# MDR1986VK01 register map
File version: 1.0.2
Registers are 32-bit, read-write, no defined reset value unless marked. A register's access mark holds for its fields unless they carry their own. Offsets are from the block's base; [hi:lo] are bit positions; {n}, {i} and the like mark numbered series; 'fields as' and 'values as' point back to an identical list.

## MDR_BKP — MDR_BKP description
Base 0x40001000
{0x0+4i} REG_{i:02} (i=0..59)
0xF0 KEY — KEY description
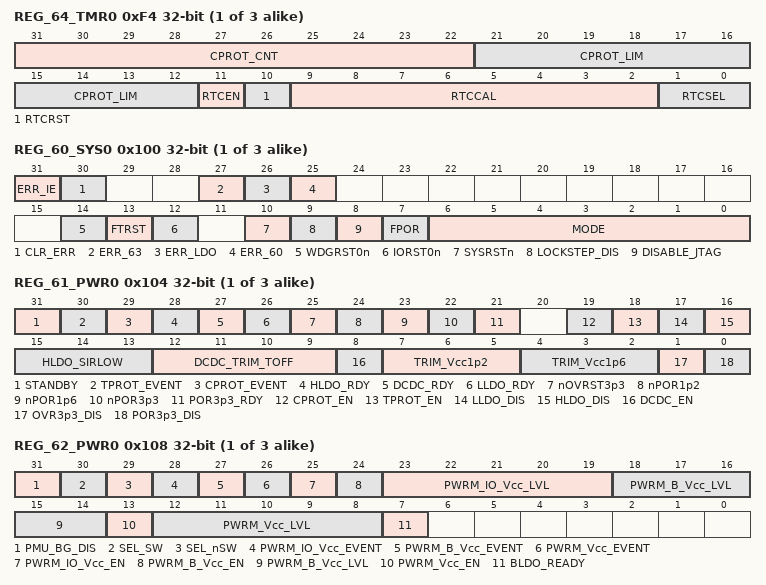
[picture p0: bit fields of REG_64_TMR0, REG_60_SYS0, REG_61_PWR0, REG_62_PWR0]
{0xF4+4i} REG_64_TMR{i} (i=0..2) — REG_64_TMR{i} description
  [31:22] CPROT_CNT ro — CPROT_CNT description
  [21:12] CPROT_LIM — CPROT_LIM description
  [11] RTCEN — RTCEN description
  [10] RTCRST — RTCRST description
  [9:2] RTCCAL — RTCCAL description
  [1:0] RTCSEL — RTCSEL description
    0=LSI (LSI selected); 1=LSE (LSE selected); 2=RTC_CLK (RTC_CLK selected)
{0x100+0x10*i} REG_60_SYS{i} (i=0..2) — REG_60_SYS{i} description
  [31] ERR_IE — ERR_IE description
  [30] CLR_ERR — CLR_ERR description
  [27] ERR_63 — ERR_63 description
  [26] ERR_LDO — ERR_LDO description
  [25] ERR_60 — ERR_60 description
  [14] WDGRST0n — WDGRST0n description
  [13] FTRST — FTRST description
  [12] IORST0n — IORST0n description
  [10] SYSRSTn — SYSRSTn description
  [9] LOCKSTEP_DIS — LOCKSTEP_DIS description
  [8] DISABLE_JTAG — DISABLE_JTAG description
  [7] FPOR — FPOR description
  [6:0] MODE — MODE description
{0x104+0x10*i} REG_61_PWR{i} (i=0..2) — REG_61_PWR{i} description
  [31] STANDBY — STANDBY description
  [30] TPROT_EVENT ro — TPROT_EVENT description
  [29] CPROT_EVENT ro — CPROT_EVENT description
  [28] HLDO_RDY ro — HLDO_RDY description
  [27] DCDC_RDY ro — DCDC_RDY description
  [26] LLDO_RDY ro — LLDO_RDY description
  [25] nOVRST3p3 ro — nOVRST3p3 description
  [24] nPOR1p2 ro — nPOR1p2 description
  [23] nPOR1p6 ro — nPOR1p6 description
  [22] nPOR3p3 ro — nPOR3p3 description
  [21] POR3p3_RDY ro — POR3p3_RDY description
  [19] CPROT_EN — CPROT_EN description
  [18] TPROT_EN — TPROT_EN description
  [17] LLDO_DIS — LLDO_DIS description
  [16] HLDO_DIS — HLDO_DIS description
  [15:13] HLDO_SIRLOW — HLDO_SIRLOW description
  [12:9] DCDC_TRIM_TOFF — DCDC_TRIM_TOFF description
  [8] DCDC_EN — DCDC_EN description
  [7:5] TRIM_Vcc1p2 — TRIM_Vcc1p2 description
  [4:2] TRIM_Vcc1p6 — TRIM_Vcc1p6 description
  [1] OVR3p3_DIS — OVR3p3_DIS description
  [0] POR3p3_DIS — POR3p3_DIS description
{0x108+0x10*i} REG_62_PWR{i} (i=0..2) — REG_62_PWR{i} description
  [31] PMU_BG_DIS — PMU_BG_DIS description
  [30] SEL_SW ro — SEL_SW description
  [29] SEL_nSW ro — SEL_nSW description
  [28] PWRM_IO_Vcc_EVENT ro — PWRM_IO_Vcc_EVENT description
  [27] PWRM_B_Vcc_EVENT ro — PWRM_B_Vcc_EVENT description
  [26] PWRM_Vcc_EVENT ro — PWRM_Vcc_EVENT description
  [25] PWRM_IO_Vcc_EN — PWRM_IO_Vcc_EN description
  [24] PWRM_B_Vcc_EN — PWRM_B_Vcc_EN description
  [23:19] PWRM_IO_Vcc_LVL — PWRM_IO_Vcc_LVL description
  [18:14] PWRM_B_Vcc_LVL — PWRM_B_Vcc_LVL description
  [13] PWRM_Vcc_EN — PWRM_Vcc_EN description
  [12:8] PWRM_Vcc_LVL — PWRM_Vcc_LVL description
  [7] BLDO_READY ro — BLDO_READY description
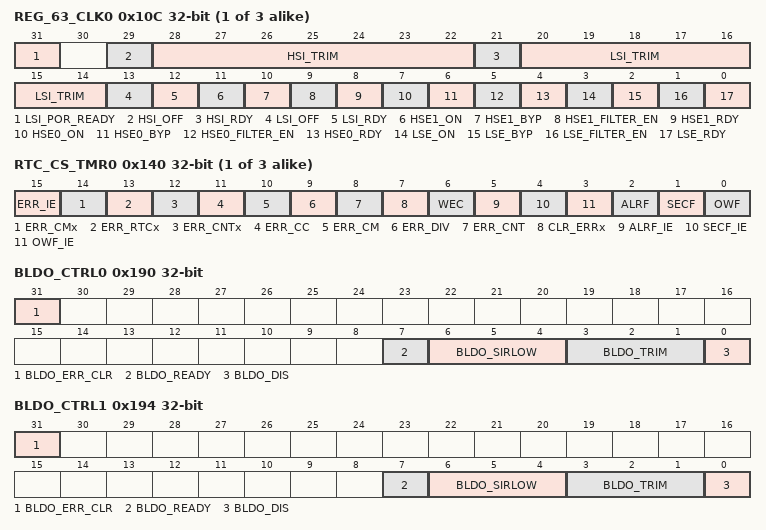
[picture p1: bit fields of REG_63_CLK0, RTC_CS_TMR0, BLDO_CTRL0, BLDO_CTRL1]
{0x10C+0x10*i} REG_63_CLK{i} (i=0..2) — REG_63_CLK{i} description
  [31] LSI_POR_READY ro — LSI_POR_READY description
  [29] HSI_OFF — HSI_OFF description
  [28:22] HSI_TRIM — HSI_TRIM description
  [21] HSI_RDY ro — HSI_RDY description
  [20:14] LSI_TRIM — LSI_TRIM description
  [13] LSI_OFF — LSI_OFF description
  [12] LSI_RDY ro — LSI_RDY description
  [11] HSE1_ON — HSE1_ON description
  [10] HSE1_BYP — HSE1_BYP description
  [9] HSE1_FILTER_EN — HSE1_FILTER_EN description
  [8] HSE1_RDY ro — HSE1_RDY description
  [7] HSE0_ON — HSE0_ON description
  [6] HSE0_BYP — HSE0_BYP description
  [5] HSE0_FILTER_EN — HSE0_FILTER_EN description
  [4] HSE0_RDY ro — HSE0_RDY description
  [3] LSE_ON — LSE_ON description
  [2] LSE_BYP — LSE_BYP description
  [1] LSE_FILTER_EN — LSE_FILTER_EN description
  [0] LSE_RDY ro — LSE_RDY description
{0x130+0x20*i} RTC_CNT_TMR{i} (i=0..2) — RTC_CNT_TMR{i} description
{0x134+0x20*i} RTC_DIV_TMR{i} (i=0..2) — RTC_DIV_TMR{i} description
  [19:0] DIV — DIV description
{0x138+0x20*i} RTC_PRL_TMR{i} (i=0..2) — RTC_PRL_TMR{i} description
  [19:0] PRL — PRL description
{0x13C+0x20*i} RTC_ALRM_TMR{i} (i=0..2) — RTC_ALRM_TMR{i} description
{0x140+0x20*i} RTC_CS_TMR{i} (i=0..2) — RTC_CS_TMR{i} description
  [15] ERR_IE — ERR_IE description
  [14] ERR_CMx — ERR_CMx description
  [13] ERR_RTCx — ERR_RTCx description
  [12] ERR_CNTx — ERR_CNTx description
  [11] ERR_CC — ERR_CC description
  [10] ERR_CM — ERR_CM description
  [9] ERR_DIV — ERR_DIV description
  [8] ERR_CNT — ERR_CNT description
  [7] CLR_ERRx — CLR_ERRx description
  [6] WEC ro — WEC description
  [5] ALRF_IE — ALRF_IE description
  [4] SECF_IE — SECF_IE description
  [3] OWF_IE — OWF_IE description
  [2] ALRF — ALRF description
  [1] SECF — SECF description
  [0] OWF — OWF description
0x190 BLDO_CTRL0 — BLDO_CTRL0 description
  [31] BLDO_ERR_CLR — BLDO_ERR_CLR description
  [7] BLDO_READY ro — BLDO_READY description
  [6:4] BLDO_SIRLOW — BLDO_SIRLOW description
  [3:1] BLDO_TRIM — BLDO_TRIM description
  [0] BLDO_DIS — BLDO_DIS description
0x194 BLDO_CTRL1 — BLDO_CTRL1 description
  fields as BLDO_CTRL0
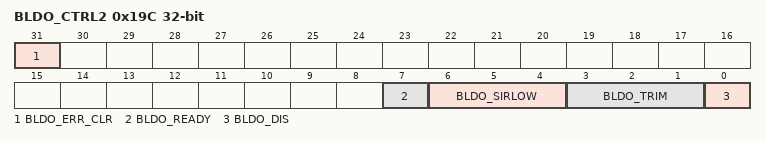
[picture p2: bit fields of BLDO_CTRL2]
0x19C BLDO_CTRL2 — BLDO_CTRL2 description
  fields as BLDO_CTRL0
